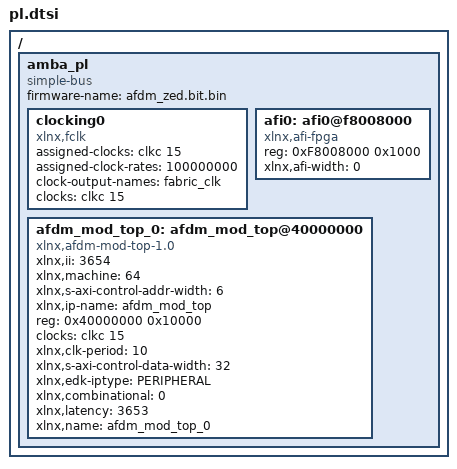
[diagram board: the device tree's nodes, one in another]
/ {
	amba_pl: amba_pl {
		ranges;
		compatible = "simple-bus";
		#address-cells = <1>;
		#size-cells = <1>;
		firmware-name = "afdm_zed.bit.bin";
		clocking0: clocking0 {
			compatible = "xlnx,fclk";
			assigned-clocks = <&clkc 15>;
			assigned-clock-rates = <100000000>;
			#clock-cells = <0>;
			clock-output-names = "fabric_clk";
			clocks = <&clkc 15>;
		};
		afi0: afi0@f8008000 {
			status = "okay";
			compatible = "xlnx,afi-fpga";
			#address-cells = <1>;
			reg = <0xF8008000 0x1000>;
			#size-cells = <0>;
			xlnx,afi-width = <0>;
		};
		afdm_mod_top_0: afdm_mod_top@40000000 {
			compatible = "xlnx,afdm-mod-top-1.0";
			xlnx,ii = <3654>;
			xlnx,machine = <64>;
			xlnx,s-axi-control-addr-width = <6>;
			xlnx,ip-name = "afdm_mod_top";
			reg = <0x40000000 0x10000>;
			clocks = <&clkc 15>;
			xlnx,clk-period = <10>;
			xlnx,s-axi-control-data-width = <32>;
			xlnx,edk-iptype = "PERIPHERAL";
			status = "okay";
			clock-names = "ap_clk";
			xlnx,combinational = <0>;
			xlnx,latency = <3653>;
			xlnx,name = "afdm_mod_top_0";
		};
	};
};
